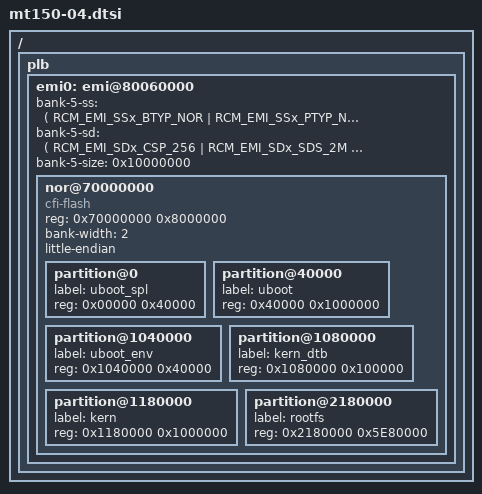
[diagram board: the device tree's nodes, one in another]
/*
 * Device Tree Source for RCM MB115.04 extention board (NOR)
 *
 * Copyright (C) 2020 MIR
 *	Mikhail.Petrov@mir.dev
 *
 * SPDX-License-Identifier: GPL-2.0+
 */

/ {
	plb {
		emi0: emi@80060000 {
			status = "ok";
			bank-5-ss = <(
				RCM_EMI_SSx_BTYP_NOR
				| RCM_EMI_SSx_PTYP_NO_PAGES
				| RCM_EMI_SSx_SRDY_EXT_RDY_NOT_USE
				| RCM_EMI_SSx_TWR_0
				| RCM_EMI_SSx_SST_FLOW_THROUGH
				| RCM_EMI_SSx_TSSOE_1
				| RCM_EMI_SSx_TSOE_1
				| RCM_EMI_SSx_TCYC_12
				| RCM_EMI_SSx_RDY(0)
				| RCM_EMI_SSx_TDEL_0)>;
			bank-5-sd = <(
				RCM_EMI_SDx_CSP_256
				| RCM_EMI_SDx_SDS_2M
				| RCM_EMI_SDx_CL_3
				| RCM_EMI_SDx_TRDL_1
				| RCM_EMI_SDx_SI_EXT_INIT
				| RCM_EMI_SDx_T_RCD_5
				| RCM_EMI_SDx_T_RAS_9)>;
			// bank-5-ecc; // cannot be used with NOR
			bank-5-size = <0x10000000>; // whole slot

			nor@70000000 {
				compatible = "cfi-flash";
				reg = <0x70000000 0x8000000>; // 128 MB
				bank-width = <2>;
				#size-cells = <1>;
				#address-cells = <1>;
				little-endian;

				partition@0 {
					label = "uboot_spl";
					reg = <0x00000 0x40000>;
				};

				partition@40000 {
					label = "uboot";
					reg = <0x40000 0x1000000>;
				};

				partition@1040000 {
					label = "uboot_env";
					reg = <0x1040000 0x40000>;
				};

				partition@1080000 {
					label = "kern_dtb";
					reg = <0x1080000 0x100000>;
				};

				partition@1180000 {
					label = "kern";
					reg = <0x1180000 0x1000000>;
				};

				partition@2180000 {
					label = "rootfs";
					reg = <0x2180000 0x5E80000>;
				};
			};
		};
	};
};
